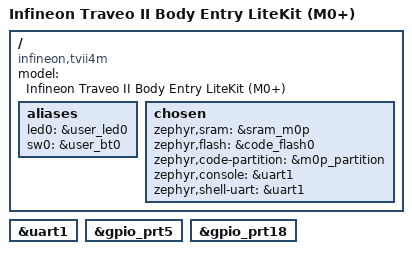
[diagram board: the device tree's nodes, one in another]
/*
 * Copyright (c) 2026 Linumiz
 * Copyright (c) 2026 Infineon Technologies AG
 * SPDX-License-Identifier: Apache-2.0
 */

/dts-v1/;

#include "kit_t2g_b_e_lite.dtsi"
#include <infineon/cat1a/cyt2bl/cyt2bl_m0p.dtsi>

/ {
	model = "Infineon Traveo II Body Entry LiteKit (M0+)";
	compatible = "infineon,tvii4m";

	aliases {
		led0 = &user_led0;
		sw0 = &user_bt0;
	};

	chosen {
		zephyr,sram = &sram_m0p;
		zephyr,flash = &code_flash0;
		zephyr,code-partition = &m0p_partition;
		zephyr,console = &uart1;
		zephyr,shell-uart = &uart1;
	};
};

&uart1 {
	status = "okay";
};

&gpio_prt5 {
	status = "okay";
};

&gpio_prt18 {
	status = "okay";
};
